# CEC1702 register map
Vendor: Microchip
Architecture arm32bit. Special function registers and configuration words.
Registers are 32-bit, read-write, reset 0x0 unless marked. A register's access mark holds for its fields unless they carry their own. Addresses are absolute, and some are shared; only a register's first bit layout is shown; lines under a group give offsets from that group; [hi:lo] are bit positions; {n}, {i} and the like mark numbered series; 'fields as' and 'values as' point back to an identical list; <NAME> marks a mode.

## Further device data
interrupts=-15 Reset — Reset Vector, invoked on Power up and warm reset; -14 NonMaskableInt — Non Maskable Interrupt; -13 HardFault — Hard Fault Interrupt; -12 MemoryManagement — Memory Management Interrupt; -11 BusFault — Bus Fault Interrupt; -10 UsageFault — Usage Fault Interrupt; -5 SVCall — SV Call Interrupt; -4 DebugMonitor — Debug Monitor Interrupt; -2 PendSV — Pend SV Interrupt; -1 SysTick — System Tick Interrupt; 0 GIRQ08; 1 GIRQ09; 2 GIRQ10; 3 GIRQ11; 4 GIRQ12; 17 GIRQ26; 20 SMB0; 21 SMB1; 22 SMB2; 23 SMB3; 24 DMA_CH00; 25 DMA_CH01; 26 DMA_CH02; 27 DMA_CH03; 28 DMA_CH04; 29 DMA_CH05; 30 DMA_CH06; 31 DMA_CH07; 32 DMA_CH08; 33 DMA_CH09; 34 DMA_CH10; 35 DMA_CH11; 36 DMA_CH12; 37 DMA_CH13; 40 UART0; 41 UART1; 71 TACH0; 72 TACH1; 74 RPM2PWM_0_FAIL; 75 RPM2PWM_0_STALL; 76 RPM2PWM_1_FAIL; 77 RPM2PWM_1_STALL; 78 SNGL; 79 RPT; 80 RC_ID0; 81 RC_ID1; 83 LED0; 84 LED1; 91 QMSPI; 92 TX0; 93 RX0; 111 TIMER; 112 HTM0; 113 HTM1; 114 ALARM_INT; 115 WKSUB; 116 WKSEC; 117 WKSUBSEC; 118 SYSPWR; 119 RTC; 120 RTC_ALARM; 121 OVRD_IN; 122 IN0; 123 IN1; 124 IN2; 125 IN3; 126 IN4; 127 IN5; 128 IN6; 135 KMS; 136 TIMER16_0; 137 TIMER16_1; 138 TIMER16_2; 139 TIMER16_3; 140 TIMER32_0; 141 TIMER32_1; 142 CNT_TMR0; 143 CNT_TMR1; 144 CNT_TMR2; 145 CNT_TMR3; 146 CAPTURE_TIMER; 147 CAPTURE_0; 148 CAPTURE_1; 149 CAPTURE_2; 150 CAPTURE_3; 151 CAPTURE_4; 152 CAPTURE_5; 153 COMPARE_0; 154 COMPARE_1

## WDT
0x40000000 LOAD 16-bit reset 0xF
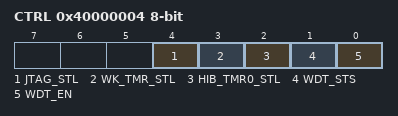
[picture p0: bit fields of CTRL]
0x40000004 CTRL 8-bit
  [4] JTAG_STL — This bit enables the WDT Stall function if JTAG or SWD debug functions are active. 1=The WDT is stalled while either JTAG or SWD is active. 0=The WDT is not affected by the JTAG debug interface.
  [3] WK_TMR_STL — This bit enables the WDT Stall function if the Week Timer is active. 1=The WDT is stalled while the Week Timer is active. 0=The WDT is not affected by the Week Timer.
  [2] HIB_TMR0_STL — This bit enables the WDT Stall function if the Hibernation Timer 0 is active. 1=The WDT is stalled while the Hibernation Timer 0 is active. 0=The WDT is not affected by Hibernation Timer 0.
  [1] WDT_STS — WDT_STS is set by hardware if the last reset of the device was caused by an underflow of the WDT. This bit must be cleared by the EC firmware writing a '1' to this bit. Writing a '0' to this bit has no effect.
  [0] WDT_EN — WDT Block enabled
0x40000008 KICK 8-bit wo
0x4000000C CNT 16-bit ro reset 0xFFFF

## TIMER16_0
0x40000C00 CNT
0x40000C04 PRLD
0x40000C08 STS
  [0] EVT_INT — This is the interrupt status that fires when the timer reaches its limit. This is the interrupt status that fires when the timer reaches its limit. This may be level or a self clearing signal cycle pulse, based on the AUTO_RESTART bit in the Timer. Control Register. If the timer is set to automatically restart, it will provide a pulse, otherwise a level is provided.(R/WC)
0x40000C0C IEN
  [0] EN — This is the interrupt enable for the status EVENT_INTERRUPT bit in the Timer Status Register.
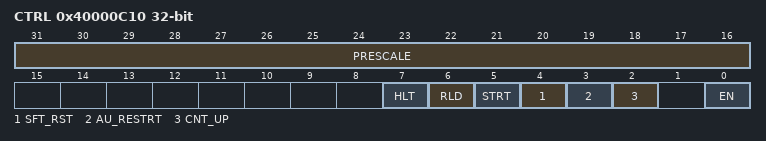
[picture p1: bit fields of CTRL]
0x40000C10 CTRL
  [31:16] PRESCALE — This is used to divide down the system clock through clock enables to lower the power consumption of the block and allow slow timers. Updating this value during operation may result in erroneous clock enable pulses until the clock divider restarts. The number of clocks per clock enable pulse is (Value + 1); a setting of 0 runs at the full clock speed, while a setting of 1 runs at half speed.
  [7] HLT — This is a halt bit. This will halt the timer as long as it is active. Once the halt is inactive, the timer will start from where it left off. 1=Timer is halted. It stops counting. The clock divider will also be reset. 0=Timer runs normally.
  [6] RLD — This bit reloads the counter without interrupting it operation. This will not function if the timer has already completed (when the START bit in this register is '0'). This is used to periodically prevent the timer from firing when an event occurs. Usage while the timer is off may result in erroneous behaviour.
  [5] STRT — This bit triggers the timer counter. The counter will operate until it hits its terminating condition. This will clear this bit. It should be noted that when operating in restart mode, there is no terminating condition for the counter, so this bit will never clear. Clearing this bit will halt the timer counter.
  [4] SFT_RST — This is a soft reset. This is self clearing 1 cycle after it is written. Firmware does not need to wait before reconfiguring the Basic Timer following soft reset.
  [3] AU_RESTRT — This will select the action taken upon completing a count. 1=The counter will automatically restart the count, using the contents of the Timer Preload Register to load the Timer Count Register. The interrupt will be set in edge mode. 0=The counter will simply enter a done state and wait for further control inputs. The interrupt will be set in level mode.
  [2] CNT_UP — This selects the counter direction. When the counter in incrementing the counter will saturate and trigger the event when it reaches all F's. When the counter is decrementing the counter will saturate when it reaches 0h. 1=The counter will increment; 0=The counter will decrement
  [0] EN — This enables the block for operation. 1=This block will function normally; 0=This block will gate its clock and go into its lowest power state
